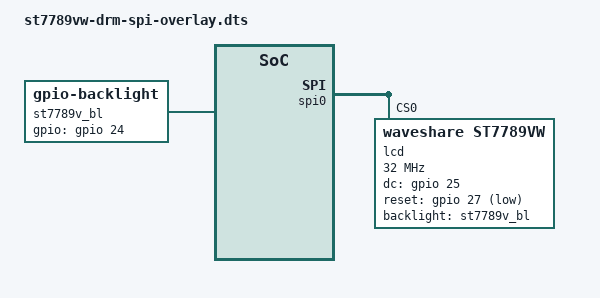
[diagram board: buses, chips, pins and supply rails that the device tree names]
/dts-v1/;
/plugin/;
#include <dt-bindings/gpio/gpio.h>

/ {
	compatible="brcm,brcm2835";
	
	fragment@0 {
		target = <&spidev0>;
		__overlay__ {
			status = "disabled";
		};
	};

	fragment@1 {
		target = <&spidev1>;
		__overlay__ {
			status = "disabled";
		};
	};
	
	fragment@2 {
		target = <&spi0>;
		__overlay__ {
			status = "okay";
			
			#address-cells = <1>;
			#size-cells = <0>;
			
			lcd@0 {
				compatible = "waveshare,st7789vw";
				reg = <0>;
				
				spi-max-frequency = <32000000>;
				
				dc-gpios = <&gpio 25 GPIO_ACTIVE_HIGH>;
				reset-gpios = <&gpio 27 GPIO_ACTIVE_LOW>;
				backlight = <&st7789v_bl>;
				
			};
		};
	};
	
	fragment@3 {
		target-path = "/";
		
		__overlay__ {
			st7789v_bl: backlight {
				compatible = "gpio-backlight";
				gpios = <&gpio 24 GPIO_ACTIVE_HIGH>;
				default-on;
			};
		};
	};
	
};
